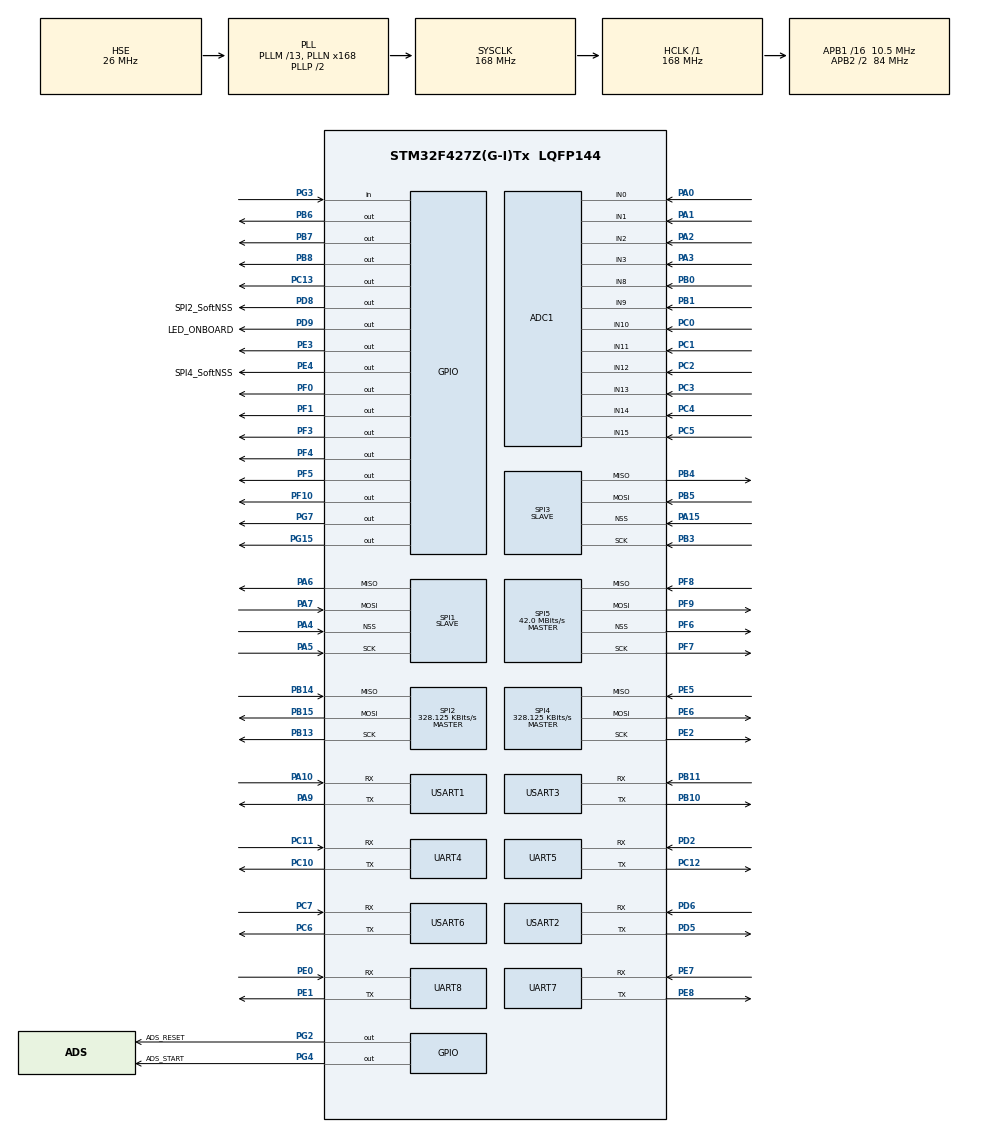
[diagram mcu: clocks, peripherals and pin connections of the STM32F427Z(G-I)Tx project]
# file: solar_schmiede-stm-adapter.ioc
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ADC1.Channel-1\#ChannelRegularConversion=ADC_CHANNEL_0
ADC1.Channel-10\#ChannelRegularConversion=ADC_CHANNEL_13
ADC1.Channel-11\#ChannelRegularConversion=ADC_CHANNEL_14
ADC1.Channel-12\#ChannelRegularConversion=ADC_CHANNEL_15
ADC1.Channel-2\#ChannelRegularConversion=ADC_CHANNEL_1
ADC1.Channel-3\#ChannelRegularConversion=ADC_CHANNEL_2
ADC1.Channel-4\#ChannelRegularConversion=ADC_CHANNEL_3
ADC1.Channel-5\#ChannelRegularConversion=ADC_CHANNEL_8
ADC1.Channel-6\#ChannelRegularConversion=ADC_CHANNEL_9
ADC1.Channel-7\#ChannelRegularConversion=ADC_CHANNEL_10
ADC1.Channel-8\#ChannelRegularConversion=ADC_CHANNEL_11
ADC1.Channel-9\#ChannelRegularConversion=ADC_CHANNEL_12
ADC1.DiscontinuousConvMode=DISABLE
ADC1.EOCSelection=ADC_EOC_SEQ_CONV
ADC1.NbrOfConversion=12
ADC1.NbrOfConversionFlag=1
ADC1.Rank-1\#ChannelRegularConversion=1
ADC1.Rank-10\#ChannelRegularConversion=10
ADC1.Rank-11\#ChannelRegularConversion=11
ADC1.Rank-12\#ChannelRegularConversion=12
ADC1.Rank-2\#ChannelRegularConversion=2
ADC1.Rank-3\#ChannelRegularConversion=3
ADC1.Rank-4\#ChannelRegularConversion=4
ADC1.Rank-5\#ChannelRegularConversion=5
ADC1.Rank-6\#ChannelRegularConversion=6
ADC1.Rank-7\#ChannelRegularConversion=7
ADC1.Rank-8\#ChannelRegularConversion=8
ADC1.Rank-9\#ChannelRegularConversion=9
ADC1.SamplingTime-1\#ChannelRegularConversion=ADC_SAMPLETIME_3CYCLES
ADC1.SamplingTime-10\#ChannelRegularConversion=ADC_SAMPLETIME_3CYCLES
ADC1.SamplingTime-11\#ChannelRegularConversion=ADC_SAMPLETIME_3CYCLES
ADC1.SamplingTime-12\#ChannelRegularConversion=ADC_SAMPLETIME_3CYCLES
ADC1.SamplingTime-2\#ChannelRegularConversion=ADC_SAMPLETIME_3CYCLES
ADC1.SamplingTime-3\#ChannelRegularConversion=ADC_SAMPLETIME_3CYCLES
ADC1.SamplingTime-4\#ChannelRegularConversion=ADC_SAMPLETIME_3CYCLES
ADC1.SamplingTime-5\#ChannelRegularConversion=ADC_SAMPLETIME_3CYCLES
ADC1.SamplingTime-6\#ChannelRegularConversion=ADC_SAMPLETIME_3CYCLES
ADC1.SamplingTime-7\#ChannelRegularConversion=ADC_SAMPLETIME_3CYCLES
ADC1.SamplingTime-8\#ChannelRegularConversion=ADC_SAMPLETIME_3CYCLES
ADC1.SamplingTime-9\#ChannelRegularConversion=ADC_SAMPLETIME_3CYCLES
ADC1.ScanConvMode=ENABLE
ADC1.master=1
Dma.ADC1.0.Direction=DMA_PERIPH_TO_MEMORY
Dma.ADC1.0.FIFOMode=DMA_FIFOMODE_DISABLE
Dma.ADC1.0.Instance=DMA2_Stream0
Dma.ADC1.0.MemDataAlignment=DMA_MDATAALIGN_HALFWORD
Dma.ADC1.0.MemInc=DMA_MINC_ENABLE
Dma.ADC1.0.Mode=DMA_NORMAL
Dma.ADC1.0.PeriphDataAlignment=DMA_PDATAALIGN_HALFWORD
Dma.ADC1.0.PeriphInc=DMA_PINC_DISABLE
Dma.ADC1.0.Priority=DMA_PRIORITY_LOW
Dma.Request0=ADC1
Dma.Request1=USART6_RX
Dma.Request2=USART3_RX
Dma.Request3=USART2_RX
Dma.Request4=USART1_RX
Dma.Request5=UART8_RX
Dma.Request6=UART7_RX
Dma.Request7=UART5_RX
Dma.Request8=UART4_RX
Dma.UART4_RX.8.Direction=DMA_PERIPH_TO_MEMORY
Dma.UART4_RX.8.FIFOMode=DMA_FIFOMODE_DISABLE
Dma.UART4_RX.8.Instance=DMA1_Stream2
Dma.UART4_RX.8.MemDataAlignment=DMA_MDATAALIGN_BYTE
Dma.UART4_RX.8.MemInc=DMA_MINC_ENABLE
Dma.UART4_RX.8.Mode=DMA_NORMAL
Dma.UART4_RX.8.PeriphDataAlignment=DMA_PDATAALIGN_BYTE
Dma.UART4_RX.8.PeriphInc=DMA_PINC_DISABLE
Dma.UART4_RX.8.Priority=DMA_PRIORITY_LOW
Dma.UART5_RX.7.Direction=DMA_PERIPH_TO_MEMORY
Dma.UART5_RX.7.FIFOMode=DMA_FIFOMODE_DISABLE
Dma.UART5_RX.7.Instance=DMA1_Stream0
Dma.UART5_RX.7.MemDataAlignment=DMA_MDATAALIGN_BYTE
Dma.UART5_RX.7.MemInc=DMA_MINC_ENABLE
Dma.UART5_RX.7.Mode=DMA_NORMAL
Dma.UART5_RX.7.PeriphDataAlignment=DMA_PDATAALIGN_BYTE
Dma.UART5_RX.7.PeriphInc=DMA_PINC_DISABLE
Dma.UART5_RX.7.Priority=DMA_PRIORITY_LOW
Dma.UART7_RX.6.Direction=DMA_PERIPH_TO_MEMORY
Dma.UART7_RX.6.FIFOMode=DMA_FIFOMODE_DISABLE
Dma.UART7_RX.6.Instance=DMA1_Stream3
Dma.UART7_RX.6.MemDataAlignment=DMA_MDATAALIGN_BYTE
Dma.UART7_RX.6.MemInc=DMA_MINC_ENABLE
Dma.UART7_RX.6.Mode=DMA_NORMAL
Dma.UART7_RX.6.PeriphDataAlignment=DMA_PDATAALIGN_BYTE
Dma.UART7_RX.6.PeriphInc=DMA_PINC_DISABLE
Dma.UART7_RX.6.Priority=DMA_PRIORITY_LOW
Dma.UART8_RX.5.Direction=DMA_PERIPH_TO_MEMORY
Dma.UART8_RX.5.FIFOMode=DMA_FIFOMODE_DISABLE
Dma.UART8_RX.5.Instance=DMA1_Stream6
Dma.UART8_RX.5.MemDataAlignment=DMA_MDATAALIGN_BYTE
Dma.UART8_RX.5.MemInc=DMA_MINC_ENABLE
Dma.UART8_RX.5.Mode=DMA_NORMAL
Dma.UART8_RX.5.PeriphDataAlignment=DMA_PDATAALIGN_BYTE
Dma.UART8_RX.5.PeriphInc=DMA_PINC_DISABLE
Dma.UART8_RX.5.Priority=DMA_PRIORITY_LOW
Dma.USART1_RX.4.Direction=DMA_PERIPH_TO_MEMORY
Dma.USART1_RX.4.FIFOMode=DMA_FIFOMODE_DISABLE
Dma.USART1_RX.4.Instance=DMA2_Stream2
Dma.USART1_RX.4.MemDataAlignment=DMA_MDATAALIGN_BYTE
Dma.USART1_RX.4.MemInc=DMA_MINC_ENABLE
Dma.USART1_RX.4.Mode=DMA_NORMAL
Dma.USART1_RX.4.PeriphDataAlignment=DMA_PDATAALIGN_BYTE
Dma.USART1_RX.4.PeriphInc=DMA_PINC_DISABLE
Dma.USART1_RX.4.Priority=DMA_PRIORITY_LOW
Dma.USART2_RX.3.Direction=DMA_PERIPH_TO_MEMORY
Dma.USART2_RX.3.FIFOMode=DMA_FIFOMODE_DISABLE
Dma.USART2_RX.3.Instance=DMA1_Stream5
Dma.USART2_RX.3.MemDataAlignment=DMA_MDATAALIGN_BYTE
Dma.USART2_RX.3.MemInc=DMA_MINC_ENABLE
Dma.USART2_RX.3.Mode=DMA_NORMAL
Dma.USART2_RX.3.PeriphDataAlignment=DMA_PDATAALIGN_BYTE
Dma.USART2_RX.3.PeriphInc=DMA_PINC_DISABLE
Dma.USART2_RX.3.Priority=DMA_PRIORITY_LOW
Dma.USART3_RX.2.Direction=DMA_PERIPH_TO_MEMORY
Dma.USART3_RX.2.FIFOMode=DMA_FIFOMODE_DISABLE
Dma.USART3_RX.2.Instance=DMA1_Stream1
Dma.USART3_RX.2.MemDataAlignment=DMA_MDATAALIGN_BYTE
Dma.USART3_RX.2.MemInc=DMA_MINC_ENABLE
Dma.USART3_RX.2.Mode=DMA_NORMAL
Dma.USART3_RX.2.PeriphDataAlignment=DMA_PDATAALIGN_BYTE
Dma.USART3_RX.2.PeriphInc=DMA_PINC_DISABLE
Dma.USART3_RX.2.Priority=DMA_PRIORITY_LOW
Dma.USART6_RX.1.Direction=DMA_PERIPH_TO_MEMORY
Dma.USART6_RX.1.FIFOMode=DMA_FIFOMODE_DISABLE
Dma.USART6_RX.1.Instance=DMA2_Stream1
Dma.USART6_RX.1.MemDataAlignment=DMA_MDATAALIGN_BYTE
Dma.USART6_RX.1.MemInc=DMA_MINC_ENABLE
Dma.USART6_RX.1.Mode=DMA_NORMAL
Dma.USART6_RX.1.PeriphDataAlignment=DMA_PDATAALIGN_BYTE
Dma.USART6_RX.1.PeriphInc=DMA_PINC_DISABLE
Dma.USART6_RX.1.Priority=DMA_PRIORITY_LOW
FREERTOS.BinarySemaphores01=spi_rx,Dynamic,NULL,Depleted
FREERTOS.Mutexes01=adcBufReadMutex,Dynamic,NULL,Available
FREERTOS.Queues01=uartQueue,20,17,1,Dynamic,NULL,NULL
FREERTOS.Tasks01=defaultTask,24,128,StartDefaultTask,Default,NULL,Dynamic,NULL,NULL;logTask,41,128,logTaskEntry,Default,NULL,Dynamic,NULL,NULL;adcReadTask,24,128,adcReadTaskEntry,Default,NULL,Dynamic,NULL,NULL;huartTask,26,256,huartTaskEntry,As external,NULL,Dynamic,NULL,NULL;adsReadTask,24,128,adsTaskEntry,Default,NULL,Dynamic,NULL,NULL
FREERTOS.configUSE_NEWLIB_REENTRANT=1
FREERTOS.configUSE_PREEMPTION=1
Mcu.Family=STM32F4
Mcu.Name=STM32F427Z(G-I)Tx
Mcu.Package=LQFP144
Mcu.UserConstants=mbus_uart_baud,2400
NVIC.DMA1_Stream0_IRQn=true\:5\:0\:false\:false\:true\:true\:false\:true\:true
NVIC.DMA1_Stream1_IRQn=true\:5\:0\:false\:false\:true\:true\:false\:true\:true
NVIC.DMA1_Stream2_IRQn=true\:5\:0\:false\:false\:true\:true\:false\:true\:true
NVIC.DMA1_Stream3_IRQn=true\:5\:0\:false\:false\:true\:true\:false\:true\:true
NVIC.DMA1_Stream5_IRQn=true\:5\:0\:false\:false\:true\:true\:false\:true\:true
NVIC.DMA1_Stream6_IRQn=true\:5\:0\:false\:false\:true\:true\:false\:true\:true
NVIC.DMA2_Stream0_IRQn=true\:5\:0\:false\:false\:true\:true\:false\:true\:true
NVIC.DMA2_Stream1_IRQn=true\:5\:0\:false\:false\:true\:true\:false\:true\:true
NVIC.DMA2_Stream2_IRQn=true\:5\:0\:false\:false\:true\:true\:false\:true\:true
NVIC.PriorityGroup=NVIC_PRIORITYGROUP_4
NVIC.TIM6_DAC_IRQn=true\:15\:0\:false\:false\:true\:false\:false\:true\:true
NVIC.TimeBase=TIM6_DAC_IRQn
NVIC.TimeBaseIP=TIM6
PA0/WKUP.Signal=ADCx_IN0
PA1.Signal=ADCx_IN1
PA10.Mode=Asynchronous
PA10.Signal=USART1_RX
PA13.Mode=Serial_Wire
PA13.Signal=SYS_JTMS-SWDIO
PA14.Mode=Serial_Wire
PA14.Signal=SYS_JTCK-SWCLK
PA15.GPIO_Speed=GPIO_SPEED_FREQ_VERY_HIGH
PA15.Mode=NSS_Signal_Hard_Input
PA15.Signal=SPI3_NSS
PA2.Signal=ADCx_IN2
PA3.Signal=ADCx_IN3
PA4.Mode=NSS_Signal_Hard_Input
PA4.Signal=SPI1_NSS
PA5.GPIO_Speed=GPIO_SPEED_FREQ_VERY_HIGH
PA5.Mode=Full_Duplex_Slave
PA5.Signal=SPI1_SCK
PA6.GPIO_Mode=GPIO_MODE_AF_PP
PA6.GPIO_PuPd=GPIO_NOPULL
PA6.GPIO_Speed=GPIO_SPEED_FREQ_VERY_HIGH
PA6.Mode=Full_Duplex_Slave
PA6.Signal=SPI1_MISO
PA7.GPIO_Speed=GPIO_SPEED_FREQ_VERY_HIGH
PA7.Mode=Full_Duplex_Slave
PA7.Signal=SPI1_MOSI
PA9.Mode=Asynchronous
PA9.Signal=USART1_TX
PB0.Signal=ADCx_IN8
PB1.Signal=ADCx_IN9
PB10.Mode=Asynchronous
PB10.Signal=USART3_TX
PB11.Mode=Asynchronous
PB11.Signal=USART3_RX
PB13.Mode=Full_Duplex_Master
PB13.Signal=SPI2_SCK
PB14.Mode=Full_Duplex_Master
PB14.Signal=SPI2_MISO
PB15.Mode=Full_Duplex_Master
PB15.Signal=SPI2_MOSI
PB3.GPIO_Speed=GPIO_SPEED_FREQ_VERY_HIGH
PB3.Mode=Full_Duplex_Slave
PB3.Signal=SPI3_SCK
PB4.GPIO_Speed=GPIO_SPEED_FREQ_VERY_HIGH
PB4.Mode=Full_Duplex_Slave
PB4.Signal=SPI3_MISO
PB5.GPIO_Speed=GPIO_SPEED_FREQ_VERY_HIGH
PB5.Mode=Full_Duplex_Slave
PB5.Signal=SPI3_MOSI
PB6.Signal=GPIO_Output
PB7.Signal=GPIO_Output
PB8.Signal=GPIO_Output
PC0.Signal=ADCx_IN10
PC1.Signal=ADCx_IN11
PC10.Mode=Asynchronous
PC10.Signal=UART4_TX
PC11.Mode=Asynchronous
PC11.Signal=UART4_RX
PC12.Mode=Asynchronous
PC12.Signal=UART5_TX
PC13.Signal=GPIO_Output
PC2.Signal=ADCx_IN12
PC3.Signal=ADCx_IN13
PC4.Signal=ADCx_IN14
PC5.Signal=ADCx_IN15
PC6.Mode=Asynchronous
PC6.Signal=USART6_TX
PC7.Mode=Asynchronous
PC7.Signal=USART6_RX
PD2.Mode=Asynchronous
PD2.Signal=UART5_RX
PD5.Mode=Asynchronous
PD5.Signal=USART2_TX
PD6.Mode=Asynchronous
PD6.Signal=USART2_RX
PD8.GPIO_Label=SPI2_SoftNSS
PD8.Signal=GPIO_Output
PD9.GPIO_Label=LED_ONBOARD
PD9.Signal=GPIO_Output
PE0.Mode=Asynchronous
PE0.Signal=UART8_RX
PE1.Mode=Asynchronous
PE1.Signal=UART8_TX
PE2.Mode=Full_Duplex_Master
PE2.Signal=SPI4_SCK
PE3.Signal=GPIO_Output
PE4.GPIO_Label=SPI4_SoftNSS
PE4.Signal=GPIO_Output
PE5.Mode=Full_Duplex_Master
PE5.Signal=SPI4_MISO
PE6.Mode=Full_Duplex_Master
PE6.Signal=SPI4_MOSI
PE7.Mode=Asynchronous
PE7.Signal=UART7_RX
PE8.Mode=Asynchronous
PE8.Signal=UART7_TX
PF0.Signal=GPIO_Output
PF1.Signal=GPIO_Output
PF10.Signal=GPIO_Output
PF3.Signal=GPIO_Output
PF4.Signal=GPIO_Output
PF5.Signal=GPIO_Output
PF6.Mode=NSS_Signal_Hard_Output
PF6.Signal=SPI5_NSS
PF7.Mode=Full_Duplex_Master
PF7.Signal=SPI5_SCK
PF8.Mode=Full_Duplex_Master
PF8.Signal=SPI5_MISO
PF9.Mode=Full_Duplex_Master
PF9.Signal=SPI5_MOSI
PG15.Signal=GPIO_Output
PG2.GPIO_Label=ADS_RESET
PG2.PinState=GPIO_PIN_SET
PG2.Signal=GPIO_Output
PG3.Signal=GPIO_Input
PG4.GPIO_Label=ADS_START
PG4.PinState=GPIO_PIN_SET
PG4.Signal=GPIO_Output
PG7.Signal=GPIO_Output
PH0/OSC_IN.Mode=HSE-External-Oscillator
PH0/OSC_IN.Signal=RCC_OSC_IN
PH1/OSC_OUT.Mode=HSE-External-Oscillator
PH1/OSC_OUT.Signal=RCC_OSC_OUT
ProjectManager.HeapSize=0x200
ProjectManager.StackSize=0x400
ProjectManager.TargetToolchain=STM32CubeIDE
RCC.48MHZClocksFreq_Value=48000000
RCC.AHBFreq_Value=168000000
RCC.APB1CLKDivider=RCC_HCLK_DIV16
RCC.APB1Freq_Value=10500000
RCC.APB1TimFreq_Value=21000000
RCC.APB2CLKDivider=RCC_HCLK_DIV2
RCC.APB2Freq_Value=84000000
RCC.APB2TimFreq_Value=168000000
RCC.CortexFreq_Value=168000000
RCC.EnbaleCSS=true
RCC.HCLKFreq_Value=168000000
RCC.HSE_VALUE=26000000
RCC.HSI_VALUE=16000000
RCC.LSE_VALUE=32768
RCC.PLLM=13
RCC.PLLN=168
RCC.PLLQ=7
RCC.PLLSourceVirtual=RCC_PLLSOURCE_HSE
RCC.SYSCLKFreq_VALUE=168000000
RCC.SYSCLKSource=RCC_SYSCLKSOURCE_PLLCLK
RCC.VCOOutputFreq_Value=336000000
SH.ADCx_IN0.0=ADC1_IN0,IN0
SH.ADCx_IN1.0=ADC1_IN1,IN1
SH.ADCx_IN10.0=ADC1_IN10,IN10
SH.ADCx_IN11.0=ADC1_IN11,IN11
SH.ADCx_IN12.0=ADC1_IN12,IN12
SH.ADCx_IN13.0=ADC1_IN13,IN13
SH.ADCx_IN14.0=ADC1_IN14,IN14
SH.ADCx_IN15.0=ADC1_IN15,IN15
SH.ADCx_IN2.0=ADC1_IN2,IN2
SH.ADCx_IN3.0=ADC1_IN3,IN3
SH.ADCx_IN8.0=ADC1_IN8,IN8
SH.ADCx_IN9.0=ADC1_IN9,IN9
SPI1.Direction=SPI_DIRECTION_2LINES
SPI1.Mode=SPI_MODE_SLAVE
SPI1.VirtualNSS=VM_NSSHARD
SPI1.VirtualType=VM_SLAVE
SPI2.BaudRatePrescaler=SPI_BAUDRATEPRESCALER_32
SPI2.CalculateBaudRate=328.125 KBits/s
SPI2.Direction=SPI_DIRECTION_2LINES
SPI2.Mode=SPI_MODE_MASTER
SPI2.VirtualType=VM_MASTER
SPI3.Direction=SPI_DIRECTION_2LINES
SPI3.Mode=SPI_MODE_SLAVE
SPI3.VirtualNSS=VM_NSSHARD
SPI3.VirtualType=VM_SLAVE
SPI4.BaudRatePrescaler=SPI_BAUDRATEPRESCALER_256
SPI4.CLKPhase=SPI_PHASE_2EDGE
SPI4.CalculateBaudRate=328.125 KBits/s
SPI4.Direction=SPI_DIRECTION_2LINES
SPI4.Mode=SPI_MODE_MASTER
SPI4.VirtualType=VM_MASTER
SPI5.BaudRatePrescaler=SPI_BAUDRATEPRESCALER_2
SPI5.CalculateBaudRate=42.0 MBits/s
SPI5.Direction=SPI_DIRECTION_2LINES
SPI5.Mode=SPI_MODE_MASTER
SPI5.VirtualNSS=VM_NSSHARD
SPI5.VirtualType=VM_MASTER
UART4.BaudRate=mbus_uart_baud
UART4.VirtualMode=Asynchronous
UART5.BaudRate=mbus_uart_baud
UART5.VirtualMode=Asynchronous
UART7.BaudRate=mbus_uart_baud
UART7.VirtualMode=Asynchronous
UART8.BaudRate=mbus_uart_baud
UART8.VirtualMode=Asynchronous
USART1.BaudRate=mbus_uart_baud
USART1.VirtualMode=VM_ASYNC
USART2.BaudRate=mbus_uart_baud
USART2.VirtualMode=VM_ASYNC
USART3.BaudRate=mbus_uart_baud
USART3.VirtualMode=VM_ASYNC
USART6.BaudRate=mbus_uart_baud
USART6.VirtualMode=VM_ASYNC
VP_FREERTOS_VS_CMSIS_V2.Mode=CMSIS_V2
VP_SYS_VS_tim6.Mode=TIM6
board=custom

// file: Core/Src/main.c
/* USER CODE BEGIN Header */
/**
 ******************************************************************************
 * @file           : main.c
 * @brief          : Main program body
 ******************************************************************************
 * @attention
 *
 * Copyright (c) 2025 STMicroelectronics.
 * All rights reserved.
 *
 * This software is licensed under terms that can be found in the LICENSE file
 * in the root directory of this software component.
 * If no LICENSE file comes with this software, it is provided AS-IS.
 *
 ******************************************************************************
 */
/* USER CODE END Header */
#include "main.h"
#include "cmsis_os.h"

/* USER CODE BEGIN Includes */

#include "string.h"
#include "bus_node.h"
#include "huart_task.h"
#include "ads124s08.h"

/* USER CODE END Includes */

ADC_HandleTypeDef hadc1;
DMA_HandleTypeDef hdma_adc1;

SPI_HandleTypeDef hspi1;
SPI_HandleTypeDef hspi2;
SPI_HandleTypeDef hspi3;
SPI_HandleTypeDef hspi4;
SPI_HandleTypeDef hspi5;

UART_HandleTypeDef huart4;
UART_HandleTypeDef huart5;
UART_HandleTypeDef huart7;
UART_HandleTypeDef huart8;
UART_HandleTypeDef huart1;
UART_HandleTypeDef huart2;
UART_HandleTypeDef huart3;
UART_HandleTypeDef huart6;
DMA_HandleTypeDef hdma_uart4_rx;
DMA_HandleTypeDef hdma_uart5_rx;
DMA_HandleTypeDef hdma_uart7_rx;
DMA_HandleTypeDef hdma_uart8_rx;
DMA_HandleTypeDef hdma_usart1_rx;
DMA_HandleTypeDef hdma_usart2_rx;
DMA_HandleTypeDef hdma_usart3_rx;
DMA_HandleTypeDef hdma_usart6_rx;

/* Definitions for defaultTask */
osThreadId_t defaultTaskHandle;
const osThreadAttr_t defaultTask_attributes = {
  .name = "defaultTask",
  .stack_size = 128 * 4,
  .priority = (osPriority_t) osPriorityNormal,
};
/* Definitions for logTask */
osThreadId_t logTaskHandle;
const osThreadAttr_t logTask_attributes = {
  .name = "logTask",
  .stack_size = 128 * 4,
  .priority = (osPriority_t) osPriorityHigh1,
};
/* Definitions for adcReadTask */
osThreadId_t adcReadTaskHandle;
const osThreadAttr_t adcReadTask_attributes = {
  .name = "adcReadTask",
  .stack_size = 128 * 4,
  .priority = (osPriority_t) osPriorityNormal,
};
/* Definitions for huartTask */
osThreadId_t huartTaskHandle;
const osThreadAttr_t huartTask_attributes = {
  .name = "huartTask",
  .stack_size = 256 * 4,
  .priority = (osPriority_t) osPriorityNormal2,
};
/* Definitions for adsReadTask */
osThreadId_t adsReadTaskHandle;
const osThreadAttr_t adsReadTask_attributes = {
  .name = "adsReadTask",
  .stack_size = 128 * 4,
  .priority = (osPriority_t) osPriorityNormal,
};
/* Definitions for uartQueue */
osMessageQueueId_t uartQueueHandle;
const osMessageQueueAttr_t uartQueue_attributes = {
  .name = "uartQueue"
};
/* Definitions for adcBufReadMutex */
osMutexId_t adcBufReadMutexHandle;
const osMutexAttr_t adcBufReadMutex_attributes = {
  .name = "adcBufReadMutex"
};
/* Definitions for spi_rx */
osSemaphoreId_t spi_rxHandle;
const osSemaphoreAttr_t spi_rx_attributes = {
  .name = "spi_rx"
};

void SystemClock_Config(void);
static void MX_GPIO_Init(void);
static void MX_DMA_Init(void);
static void MX_SPI1_Init(void);
static void MX_UART4_Init(void);
static void MX_UART5_Init(void);
static void MX_UART7_Init(void);
static void MX_UART8_Init(void);
static void MX_USART1_UART_Init(void);
static void MX_USART2_UART_Init(void);
static void MX_USART3_UART_Init(void);
static void MX_USART6_UART_Init(void);
static void MX_SPI3_Init(void);
static void MX_SPI4_Init(void);
static void MX_SPI5_Init(void);
static void MX_ADC1_Init(void);
static void MX_SPI2_Init(void);
void StartDefaultTask(void *argument);
void logTaskEntry(void *argument);
void adcReadTaskEntry(void *argument);
extern void huartTaskEntry(void *argument);
void adsTaskEntry(void *argument);

/* USER CODE BEGIN 0 */

uint16_t adcReadings[12] = { 0 };
uint16_t externalADCReadings[11] = { 0 };
volatile int isADCFinished = 0;

void HAL_ADC_ConvCpltCallback(ADC_HandleTypeDef *hadc) {
	isADCFinished = 1;
}

/* USER CODE END 0 */

int main(void)
{

  /* MCU Configuration--------------------------------------------------------*/

  /* Reset of all peripherals, Initializes the Flash interface and the Systick. */
  HAL_Init();

  /* Configure the system clock */
  SystemClock_Config();

  /* Initialize all configured peripherals */
  MX_GPIO_Init();
  MX_DMA_Init();
  MX_SPI1_Init();
  MX_UART4_Init();
  MX_UART5_Init();
  MX_UART7_Init();
  MX_UART8_Init();
  MX_USART1_UART_Init();
  MX_USART2_UART_Init();
  MX_USART3_UART_Init();
  MX_USART6_UART_Init();
  MX_SPI3_Init();
  MX_SPI4_Init();
  MX_SPI5_Init();
  MX_ADC1_Init();
  MX_SPI2_Init();

  /* Init scheduler */
  osKernelInitialize();
  /* Create the mutex(es) */
  /* creation of adcBufReadMutex */
  adcBufReadMutexHandle = osMutexNew(&adcBufReadMutex_attributes);

  /* Create the semaphores(s) */
  /* creation of spi_rx */
  spi_rxHandle = osSemaphoreNew(1, 0, &spi_rx_attributes);

  /* Create the queue(s) */
  /* creation of uartQueue */
  uartQueueHandle = osMessageQueueNew (20, 17, &uartQueue_attributes);

  /* Create the thread(s) */
  /* creation of defaultTask */
  defaultTaskHandle = osThreadNew(StartDefaultTask, NULL, &defaultTask_attributes);

  /* creation of logTask */
  logTaskHandle = osThreadNew(logTaskEntry, NULL, &logTask_attributes);

  /* creation of adcReadTask */
  adcReadTaskHandle = osThreadNew(adcReadTaskEntry, NULL, &adcReadTask_attributes);

  /* creation of huartTask */
  huartTaskHandle = osThreadNew(huartTaskEntry, NULL, &huartTask_attributes);

  /* creation of adsReadTask */
  adsReadTaskHandle = osThreadNew(adsTaskEntry, NULL, &adsReadTask_attributes);

  /* Start scheduler */
  osKernelStart();

  /* We should never get here as control is now taken by the scheduler */

  /* Infinite loop */
	while (1) {

	}
}

void SystemClock_Config(void)
{
  RCC_OscInitTypeDef RCC_OscInitStruct = {0};
  RCC_ClkInitTypeDef RCC_ClkInitStruct = {0};

  /** Configure the main internal regulator output voltage
  */
  __HAL_RCC_PWR_CLK_ENABLE();
  __HAL_PWR_VOLTAGESCALING_CONFIG(PWR_REGULATOR_VOLTAGE_SCALE1);

  /** Initializes the RCC Oscillators according to the specified parameters
  * in the RCC_OscInitTypeDef structure.
  */
  RCC_OscInitStruct.OscillatorType = RCC_OSCILLATORTYPE_HSE;
  RCC_OscInitStruct.HSEState = RCC_HSE_ON;
  RCC_OscInitStruct.PLL.PLLState = RCC_PLL_ON;
  RCC_OscInitStruct.PLL.PLLSource = RCC_PLLSOURCE_HSE;
  RCC_OscInitStruct.PLL.PLLM = 13;
  RCC_OscInitStruct.PLL.PLLN = 168;
  RCC_OscInitStruct.PLL.PLLP = RCC_PLLP_DIV2;
  RCC_OscInitStruct.PLL.PLLQ = 7;
  if (HAL_RCC_OscConfig(&RCC_OscInitStruct) != HAL_OK)
  {
    Error_Handler();
  }

  /** Initializes the CPU, AHB and APB buses clocks
  */
  RCC_ClkInitStruct.ClockType = RCC_CLOCKTYPE_HCLK|RCC_CLOCKTYPE_SYSCLK
                              |RCC_CLOCKTYPE_PCLK1|RCC_CLOCKTYPE_PCLK2;
  RCC_ClkInitStruct.SYSCLKSource = RCC_SYSCLKSOURCE_PLLCLK;
  RCC_ClkInitStruct.AHBCLKDivider = RCC_SYSCLK_DIV1;
  RCC_ClkInitStruct.APB1CLKDivider = RCC_HCLK_DIV16;
  RCC_ClkInitStruct.APB2CLKDivider = RCC_HCLK_DIV2;

  if (HAL_RCC_ClockConfig(&RCC_ClkInitStruct, FLASH_LATENCY_5) != HAL_OK)
  {
    Error_Handler();
  }

  /** Enables the Clock Security System
  */
  HAL_RCC_EnableCSS();
}

static void MX_ADC1_Init(void)
{

  ADC_ChannelConfTypeDef sConfig = {0};

  /** Configure the global features of the ADC (Clock, Resolution, Data Alignment and number of conversion)
  */
  hadc1.Instance = ADC1;
  hadc1.Init.ClockPrescaler = ADC_CLOCK_SYNC_PCLK_DIV4;
  hadc1.Init.Resolution = ADC_RESOLUTION_12B;
  hadc1.Init.ScanConvMode = ENABLE;
  hadc1.Init.ContinuousConvMode = DISABLE;
  hadc1.Init.DiscontinuousConvMode = DISABLE;
  hadc1.Init.ExternalTrigConvEdge = ADC_EXTERNALTRIGCONVEDGE_NONE;
  hadc1.Init.ExternalTrigConv = ADC_SOFTWARE_START;
  hadc1.Init.DataAlign = ADC_DATAALIGN_RIGHT;
  hadc1.Init.NbrOfConversion = 12;
  hadc1.Init.DMAContinuousRequests = DISABLE;
  hadc1.Init.EOCSelection = ADC_EOC_SEQ_CONV;
  if (HAL_ADC_Init(&hadc1) != HAL_OK)
  {
    Error_Handler();
  }

  /** Configure for the selected ADC regular channel its corresponding rank in the sequencer and its sample time.
  */
  sConfig.Channel = ADC_CHANNEL_0;
  sConfig.Rank = 1;
  sConfig.SamplingTime = ADC_SAMPLETIME_3CYCLES;
  if (HAL_ADC_ConfigChannel(&hadc1, &sConfig) != HAL_OK)
  {
    Error_Handler();
  }

  /** Configure for the selected ADC regular channel its corresponding rank in the sequencer and its sample time.
  */
  sConfig.Channel = ADC_CHANNEL_1;
  sConfig.Rank = 2;
  if (HAL_ADC_ConfigChannel(&hadc1, &sConfig) != HAL_OK)
  {
    Error_Handler();
  }

  /** Configure for the selected ADC regular channel its corresponding rank in the sequencer and its sample time.
  */
  sConfig.Channel = ADC_CHANNEL_2;
  sConfig.Rank = 3;
  if (HAL_ADC_ConfigChannel(&hadc1, &sConfig) != HAL_OK)
  {
    Error_Handler();
  }

  /** Configure for the selected ADC regular channel its corresponding rank in the sequencer and its sample time.
  */
  sConfig.Channel = ADC_CHANNEL_3;
  sConfig.Rank = 4;
  if (HAL_ADC_ConfigChannel(&hadc1, &sConfig) != HAL_OK)
  {
    Error_Handler();
  }

  /** Configure for the selected ADC regular channel its corresponding rank in the sequencer and its sample time.
  */
  sConfig.Channel = ADC_CHANNEL_8;
  sConfig.Rank = 5;
  if (HAL_ADC_ConfigChannel(&hadc1, &sConfig) != HAL_OK)
  {
    Error_Handler();
  }

  /** Configure for the selected ADC regular channel its corresponding rank in the sequencer and its sample time.
  */
  sConfig.Channel = ADC_CHANNEL_9;
  sConfig.Rank = 6;
  if (HAL_ADC_ConfigChannel(&hadc1, &sConfig) != HAL_OK)
  {
    Error_Handler();
  }

  /** Configure for the selected ADC regular channel its corresponding rank in the sequencer and its sample time.
  */
  sConfig.Channel = ADC_CHANNEL_10;
  sConfig.Rank = 7;
  if (HAL_ADC_ConfigChannel(&hadc1, &sConfig) != HAL_OK)
  {
    Error_Handler();
  }

  /** Configure for the selected ADC regular channel its corresponding rank in the sequencer and its sample time.
  */
  sConfig.Channel = ADC_CHANNEL_11;
  sConfig.Rank = 8;
  if (HAL_ADC_ConfigChannel(&hadc1, &sConfig) != HAL_OK)
  {
    Error_Handler();
  }

  /** Configure for the selected ADC regular channel its corresponding rank in the sequencer and its sample time.
  */
  sConfig.Channel = ADC_CHANNEL_12;
  sConfig.Rank = 9;
  if (HAL_ADC_ConfigChannel(&hadc1, &sConfig) != HAL_OK)
  {
    Error_Handler();
  }

  /** Configure for the selected ADC regular channel its corresponding rank in the sequencer and its sample time.
  */
  sConfig.Channel = ADC_CHANNEL_13;
  sConfig.Rank = 10;
  if (HAL_ADC_ConfigChannel(&hadc1, &sConfig) != HAL_OK)
  {
    Error_Handler();
  }

  /** Configure for the selected ADC regular channel its corresponding rank in the sequencer and its sample time.
  */
  sConfig.Channel = ADC_CHANNEL_14;
  sConfig.Rank = 11;
  if (HAL_ADC_ConfigChannel(&hadc1, &sConfig) != HAL_OK)
  {
    Error_Handler();
  }

  /** Configure for the selected ADC regular channel its corresponding rank in the sequencer and its sample time.
  */
  sConfig.Channel = ADC_CHANNEL_15;
  sConfig.Rank = 12;
  if (HAL_ADC_ConfigChannel(&hadc1, &sConfig) != HAL_OK)
  {
    Error_Handler();
  }

}

static void MX_SPI1_Init(void)
{

  /* SPI1 parameter configuration*/
  hspi1.Instance = SPI1;
  hspi1.Init.Mode = SPI_MODE_SLAVE;
  hspi1.Init.Direction = SPI_DIRECTION_2LINES;
  hspi1.Init.DataSize = SPI_DATASIZE_8BIT;
  hspi1.Init.CLKPolarity = SPI_POLARITY_LOW;
  hspi1.Init.CLKPhase = SPI_PHASE_1EDGE;
  hspi1.Init.NSS = SPI_NSS_HARD_INPUT;
  hspi1.Init.FirstBit = SPI_FIRSTBIT_MSB;
  hspi1.Init.TIMode = SPI_TIMODE_DISABLE;
  hspi1.Init.CRCCalculation = SPI_CRCCALCULATION_DISABLE;
  hspi1.Init.CRCPolynomial = 10;
  if (HAL_SPI_Init(&hspi1) != HAL_OK)
  {
    Error_Handler();
  }

}

static void MX_SPI2_Init(void)
{

  /* SPI2 parameter configuration*/
  hspi2.Instance = SPI2;
  hspi2.Init.Mode = SPI_MODE_MASTER;
  hspi2.Init.Direction = SPI_DIRECTION_2LINES;
  hspi2.Init.DataSize = SPI_DATASIZE_8BIT;
  hspi2.Init.CLKPolarity = SPI_POLARITY_LOW;
  hspi2.Init.CLKPhase = SPI_PHASE_1EDGE;
  hspi2.Init.NSS = SPI_NSS_SOFT;
  hspi2.Init.BaudRatePrescaler = SPI_BAUDRATEPRESCALER_32;
  hspi2.Init.FirstBit = SPI_FIRSTBIT_MSB;
  hspi2.Init.TIMode = SPI_TIMODE_DISABLE;
  hspi2.Init.CRCCalculation = SPI_CRCCALCULATION_DISABLE;
  hspi2.Init.CRCPolynomial = 10;
  if (HAL_SPI_Init(&hspi2) != HAL_OK)
  {
    Error_Handler();
  }

}

static void MX_SPI3_Init(void)
{

  /* SPI3 parameter configuration*/
  hspi3.Instance = SPI3;
  hspi3.Init.Mode = SPI_MODE_SLAVE;
  hspi3.Init.Direction = SPI_DIRECTION_2LINES;
  hspi3.Init.DataSize = SPI_DATASIZE_8BIT;
  hspi3.Init.CLKPolarity = SPI_POLARITY_LOW;
  hspi3.Init.CLKPhase = SPI_PHASE_1EDGE;
  hspi3.Init.NSS = SPI_NSS_HARD_INPUT;
  hspi3.Init.FirstBit = SPI_FIRSTBIT_MSB;
  hspi3.Init.TIMode = SPI_TIMODE_DISABLE;
  hspi3.Init.CRCCalculation = SPI_CRCCALCULATION_DISABLE;
  hspi3.Init.CRCPolynomial = 10;
  if (HAL_SPI_Init(&hspi3) != HAL_OK)
  {
    Error_Handler();
  }

}

static void MX_SPI4_Init(void)
{

  /* SPI4 parameter configuration*/
  hspi4.Instance = SPI4;
  hspi4.Init.Mode = SPI_MODE_MASTER;
  hspi4.Init.Direction = SPI_DIRECTION_2LINES;
  hspi4.Init.DataSize = SPI_DATASIZE_8BIT;
  hspi4.Init.CLKPolarity = SPI_POLARITY_LOW;
  hspi4.Init.CLKPhase = SPI_PHASE_2EDGE;
  hspi4.Init.NSS = SPI_NSS_SOFT;
  hspi4.Init.BaudRatePrescaler = SPI_BAUDRATEPRESCALER_256;
  hspi4.Init.FirstBit = SPI_FIRSTBIT_MSB;
  hspi4.Init.TIMode = SPI_TIMODE_DISABLE;
  hspi4.Init.CRCCalculation = SPI_CRCCALCULATION_DISABLE;
  hspi4.Init.CRCPolynomial = 10;
  if (HAL_SPI_Init(&hspi4) != HAL_OK)
  {
    Error_Handler();
  }

}

static void MX_SPI5_Init(void)
{

  /* SPI5 parameter configuration*/
  hspi5.Instance = SPI5;
  hspi5.Init.Mode = SPI_MODE_MASTER;
  hspi5.Init.Direction = SPI_DIRECTION_2LINES;
  hspi5.Init.DataSize = SPI_DATASIZE_8BIT;
  hspi5.Init.CLKPolarity = SPI_POLARITY_LOW;
  hspi5.Init.CLKPhase = SPI_PHASE_1EDGE;
  hspi5.Init.NSS = SPI_NSS_HARD_OUTPUT;
  hspi5.Init.BaudRatePrescaler = SPI_BAUDRATEPRESCALER_2;
  hspi5.Init.FirstBit = SPI_FIRSTBIT_MSB;
  hspi5.Init.TIMode = SPI_TIMODE_DISABLE;
  hspi5.Init.CRCCalculation = SPI_CRCCALCULATION_DISABLE;
  hspi5.Init.CRCPolynomial = 10;
  if (HAL_SPI_Init(&hspi5) != HAL_OK)
  {
    Error_Handler();
  }

}

static void MX_UART4_Init(void)
{

  huart4.Instance = UART4;
  huart4.Init.BaudRate = mbus_uart_baud;
  huart4.Init.WordLength = UART_WORDLENGTH_8B;
  huart4.Init.StopBits = UART_STOPBITS_1;
  huart4.Init.Parity = UART_PARITY_NONE;
  huart4.Init.Mode = UART_MODE_TX_RX;
  huart4.Init.HwFlowCtl = UART_HWCONTROL_NONE;
  huart4.Init.OverSampling = UART_OVERSAMPLING_16;
  if (HAL_UART_Init(&huart4) != HAL_OK)
  {
    Error_Handler();
  }

}

static void MX_UART5_Init(void)
{

  huart5.Instance = UART5;
  huart5.Init.BaudRate = mbus_uart_baud;
  huart5.Init.WordLength = UART_WORDLENGTH_8B;
  huart5.Init.StopBits = UART_STOPBITS_1;
  huart5.Init.Parity = UART_PARITY_NONE;
  huart5.Init.Mode = UART_MODE_TX_RX;
  huart5.Init.HwFlowCtl = UART_HWCONTROL_NONE;
  huart5.Init.OverSampling = UART_OVERSAMPLING_16;
  if (HAL_UART_Init(&huart5) != HAL_OK)
  {
    Error_Handler();
  }

}

static void MX_UART7_Init(void)
{

  huart7.Instance = UART7;
  huart7.Init.BaudRate = mbus_uart_baud;
  huart7.Init.WordLength = UART_WORDLENGTH_8B;
  huart7.Init.StopBits = UART_STOPBITS_1;
  huart7.Init.Parity = UART_PARITY_NONE;
  huart7.Init.Mode = UART_MODE_TX_RX;
  huart7.Init.HwFlowCtl = UART_HWCONTROL_NONE;
  huart7.Init.OverSampling = UART_OVERSAMPLING_16;
  if (HAL_UART_Init(&huart7) != HAL_OK)
  {
    Error_Handler();
  }

}

static void MX_UART8_Init(void)
{

  huart8.Instance = UART8;
  huart8.Init.BaudRate = mbus_uart_baud;
  huart8.Init.WordLength = UART_WORDLENGTH_8B;
  huart8.Init.StopBits = UART_STOPBITS_1;
  huart8.Init.Parity = UART_PARITY_NONE;
  huart8.Init.Mode = UART_MODE_TX_RX;
  huart8.Init.HwFlowCtl = UART_HWCONTROL_NONE;
  huart8.Init.OverSampling = UART_OVERSAMPLING_16;
  if (HAL_UART_Init(&huart8) != HAL_OK)
  {
    Error_Handler();
  }

}

static void MX_USART1_UART_Init(void)
{

  huart1.Instance = USART1;
  huart1.Init.BaudRate = mbus_uart_baud;
  huart1.Init.WordLength = UART_WORDLENGTH_8B;
  huart1.Init.StopBits = UART_STOPBITS_1;
  huart1.Init.Parity = UART_PARITY_NONE;
  huart1.Init.Mode = UART_MODE_TX_RX;
  huart1.Init.HwFlowCtl = UART_HWCONTROL_NONE;
  huart1.Init.OverSampling = UART_OVERSAMPLING_16;
  if (HAL_UART_Init(&huart1) != HAL_OK)
  {
    Error_Handler();
  }

}

static void MX_USART2_UART_Init(void)
{

  huart2.Instance = USART2;
  huart2.Init.BaudRate = mbus_uart_baud;
  huart2.Init.WordLength = UART_WORDLENGTH_8B;
  huart2.Init.StopBits = UART_STOPBITS_1;
  huart2.Init.Parity = UART_PARITY_NONE;
  huart2.Init.Mode = UART_MODE_TX_RX;
  huart2.Init.HwFlowCtl = UART_HWCONTROL_NONE;
  huart2.Init.OverSampling = UART_OVERSAMPLING_16;
  if (HAL_UART_Init(&huart2) != HAL_OK)
  {
    Error_Handler();
  }

}

static void MX_USART3_UART_Init(void)
{

  huart3.Instance = USART3;
  huart3.Init.BaudRate = mbus_uart_baud;
  huart3.Init.WordLength = UART_WORDLENGTH_8B;
  huart3.Init.StopBits = UART_STOPBITS_1;
  huart3.Init.Parity = UART_PARITY_NONE;
  huart3.Init.Mode = UART_MODE_TX_RX;
  huart3.Init.HwFlowCtl = UART_HWCONTROL_NONE;
  huart3.Init.OverSampling = UART_OVERSAMPLING_16;
  if (HAL_UART_Init(&huart3) != HAL_OK)
  {
    Error_Handler();
  }

}

static void MX_USART6_UART_Init(void)
{

  huart6.Instance = USART6;
  huart6.Init.BaudRate = mbus_uart_baud;
  huart6.Init.WordLength = UART_WORDLENGTH_8B;
  huart6.Init.StopBits = UART_STOPBITS_1;
  huart6.Init.Parity = UART_PARITY_NONE;
  huart6.Init.Mode = UART_MODE_TX_RX;
  huart6.Init.HwFlowCtl = UART_HWCONTROL_NONE;
  huart6.Init.OverSampling = UART_OVERSAMPLING_16;
  if (HAL_UART_Init(&huart6) != HAL_OK)
  {
    Error_Handler();
  }

}

static void MX_DMA_Init(void)
{

  /* DMA controller clock enable */
  __HAL_RCC_DMA2_CLK_ENABLE();
  __HAL_RCC_DMA1_CLK_ENABLE();

  /* DMA interrupt init */
  /* DMA1_Stream0_IRQn interrupt configuration */
  HAL_NVIC_SetPriority(DMA1_Stream0_IRQn, 5, 0);
  HAL_NVIC_EnableIRQ(DMA1_Stream0_IRQn);
  /* DMA1_Stream1_IRQn interrupt configuration */
  HAL_NVIC_SetPriority(DMA1_Stream1_IRQn, 5, 0);
  HAL_NVIC_EnableIRQ(DMA1_Stream1_IRQn);
  /* DMA1_Stream2_IRQn interrupt configuration */
  HAL_NVIC_SetPriority(DMA1_Stream2_IRQn, 5, 0);
  HAL_NVIC_EnableIRQ(DMA1_Stream2_IRQn);
  /* DMA1_Stream3_IRQn interrupt configuration */
  HAL_NVIC_SetPriority(DMA1_Stream3_IRQn, 5, 0);
  HAL_NVIC_EnableIRQ(DMA1_Stream3_IRQn);
  /* DMA1_Stream5_IRQn interrupt configuration */
  HAL_NVIC_SetPriority(DMA1_Stream5_IRQn, 5, 0);
  HAL_NVIC_EnableIRQ(DMA1_Stream5_IRQn);
  /* DMA1_Stream6_IRQn interrupt configuration */
  HAL_NVIC_SetPriority(DMA1_Stream6_IRQn, 5, 0);
  HAL_NVIC_EnableIRQ(DMA1_Stream6_IRQn);
  /* DMA2_Stream0_IRQn interrupt configuration */
  HAL_NVIC_SetPriority(DMA2_Stream0_IRQn, 5, 0);
  HAL_NVIC_EnableIRQ(DMA2_Stream0_IRQn);
  /* DMA2_Stream1_IRQn interrupt configuration */
  HAL_NVIC_SetPriority(DMA2_Stream1_IRQn, 5, 0);
  HAL_NVIC_EnableIRQ(DMA2_Stream1_IRQn);
  /* DMA2_Stream2_IRQn interrupt configuration */
  HAL_NVIC_SetPriority(DMA2_Stream2_IRQn, 5, 0);
  HAL_NVIC_EnableIRQ(DMA2_Stream2_IRQn);

}

static void MX_GPIO_Init(void)
{
  GPIO_InitTypeDef GPIO_InitStruct = {0};

  /* GPIO Ports Clock Enable */
  __HAL_RCC_GPIOE_CLK_ENABLE();
  __HAL_RCC_GPIOC_CLK_ENABLE();
  __HAL_RCC_GPIOF_CLK_ENABLE();
  __HAL_RCC_GPIOH_CLK_ENABLE();
  __HAL_RCC_GPIOA_CLK_ENABLE();
  __HAL_RCC_GPIOB_CLK_ENABLE();
  __HAL_RCC_GPIOD_CLK_ENABLE();
  __HAL_RCC_GPIOG_CLK_ENABLE();

  /*Configure GPIO pin Output Level */
  HAL_GPIO_WritePin(GPIOE, GPIO_PIN_3|SPI4_SoftNSS_Pin, GPIO_PIN_RESET);

  /*Configure GPIO pin Output Level */
  HAL_GPIO_WritePin(GPIOC, GPIO_PIN_13, GPIO_PIN_RESET);

  /*Configure GPIO pin Output Level */
  HAL_GPIO_WritePin(GPIOF, GPIO_PIN_0|GPIO_PIN_1|GPIO_PIN_3|GPIO_PIN_4
                          |GPIO_PIN_5|GPIO_PIN_10, GPIO_PIN_RESET);

  /*Configure GPIO pin Output Level */
  HAL_GPIO_WritePin(GPIOD, SPI2_SoftNSS_Pin|LED_ONBOARD_Pin, GPIO_PIN_RESET);

  /*Configure GPIO pin Output Level */
  HAL_GPIO_WritePin(GPIOG, ADS_RESET_Pin|ADS_START_Pin, GPIO_PIN_SET);

  /*Configure GPIO pin Output Level */
  HAL_GPIO_WritePin(GPIOG, GPIO_PIN_7|GPIO_PIN_15, GPIO_PIN_RESET);

  /*Configure GPIO pin Output Level */
  HAL_GPIO_WritePin(GPIOB, GPIO_PIN_6|GPIO_PIN_7|GPIO_PIN_8, GPIO_PIN_RESET);

  /*Configure GPIO pins : PE3 SPI4_SoftNSS_Pin */
  GPIO_InitStruct.Pin = GPIO_PIN_3|SPI4_SoftNSS_Pin;
  GPIO_InitStruct.Mode = GPIO_MODE_OUTPUT_PP;
  GPIO_InitStruct.Pull = GPIO_NOPULL;
  GPIO_InitStruct.Speed = GPIO_SPEED_FREQ_LOW;
  HAL_GPIO_Init(GPIOE, &GPIO_InitStruct);

  /*Configure GPIO pin : PC13 */
  GPIO_InitStruct.Pin = GPIO_PIN_13;
  GPIO_InitStruct.Mode = GPIO_MODE_OUTPUT_PP;
  GPIO_InitStruct.Pull = GPIO_NOPULL;
  GPIO_InitStruct.Speed = GPIO_SPEED_FREQ_LOW;
  HAL_GPIO_Init(GPIOC, &GPIO_InitStruct);

  /*Configure GPIO pins : PF0 PF1 PF3 PF4
                           PF5 PF10 */
  GPIO_InitStruct.Pin = GPIO_PIN_0|GPIO_PIN_1|GPIO_PIN_3|GPIO_PIN_4
                          |GPIO_PIN_5|GPIO_PIN_10;
  GPIO_InitStruct.Mode = GPIO_MODE_OUTPUT_PP;
  GPIO_InitStruct.Pull = GPIO_NOPULL;
  GPIO_InitStruct.Speed = GPIO_SPEED_FREQ_LOW;
  HAL_GPIO_Init(GPIOF, &GPIO_InitStruct);

  /*Configure GPIO pins : SPI2_SoftNSS_Pin LED_ONBOARD_Pin */
  GPIO_InitStruct.Pin = SPI2_SoftNSS_Pin|LED_ONBOARD_Pin;
  GPIO_InitStruct.Mode = GPIO_MODE_OUTPUT_PP;
  GPIO_InitStruct.Pull = GPIO_NOPULL;
  GPIO_InitStruct.Speed = GPIO_SPEED_FREQ_LOW;
  HAL_GPIO_Init(GPIOD, &GPIO_InitStruct);

  /*Configure GPIO pins : ADS_RESET_Pin ADS_START_Pin PG7 PG15 */
  GPIO_InitStruct.Pin = ADS_RESET_Pin|ADS_START_Pin|GPIO_PIN_7|GPIO_PIN_15;
  GPIO_InitStruct.Mode = GPIO_MODE_OUTPUT_PP;
  GPIO_InitStruct.Pull = GPIO_NOPULL;
  GPIO_InitStruct.Speed = GPIO_SPEED_FREQ_LOW;
  HAL_GPIO_Init(GPIOG, &GPIO_InitStruct);

  /*Configure GPIO pin : PG3 */
  GPIO_InitStruct.Pin = GPIO_PIN_3;
  GPIO_InitStruct.Mode = GPIO_MODE_INPUT;
  GPIO_InitStruct.Pull = GPIO_NOPULL;
  HAL_GPIO_Init(GPIOG, &GPIO_InitStruct);

  /*Configure GPIO pins : PB6 PB7 PB8 */
  GPIO_InitStruct.Pin = GPIO_PIN_6|GPIO_PIN_7|GPIO_PIN_8;
  GPIO_InitStruct.Mode = GPIO_MODE_OUTPUT_PP;
  GPIO_InitStruct.Pull = GPIO_NOPULL;
  GPIO_InitStruct.Speed = GPIO_SPEED_FREQ_LOW;
  HAL_GPIO_Init(GPIOB, &GPIO_InitStruct);

}

void StartDefaultTask(void *argument)
{
  /* USER CODE BEGIN 5 */
	/* Infinite loop */
	for (;;) {
		osDelay(osWaitForever);
	}
  /* USER CODE END 5 */
}

void logTaskEntry(void *argument)
{
  /* USER CODE BEGIN logTaskEntry */

	BusNode_Init();

	HAL_GPIO_WritePin(SPI2_SoftNSS_GPIO_Port, SPI2_SoftNSS_Pin, GPIO_PIN_SET);
	/* Infinite loop */
	for (;;) {
		BusNode_RunLoop();
		osDelay(1);

	}
  /* USER CODE END logTaskEntry */
}

void adcReadTaskEntry(void *argument)
{
  /* USER CODE BEGIN adcReadTaskEntry */
	/* Infinite loop */

	// Initialize ADC readings array
	memset(adcReadings, 0, sizeof(adcReadings));

	// Use static buffer to avoid stack issues
	static uint16_t adcBuf[12] = { 0 };

	// Start ADC with DMA
	HAL_ADC_Start_DMA(&hadc1, (uint32_t*)adcBuf, 12);

	// Variables for timing
	uint32_t last_adc_update = 0;
	const uint32_t ADC_UPDATE_INTERVAL = 500; // 500ms interval for ADC updates

	for (;;) {
		uint32_t current_tick = osKernelGetTickCount();

		// Check if ADC conversion is complete
		if (isADCFinished == 1) {
			isADCFinished = 0;

			// Acquire mutex before updating shared data
			if (osMutexAcquire(adcBufReadMutexHandle, 100) == osOK) {
				// Copy ADC readings to shared buffer
				memcpy(adcReadings, adcBuf, sizeof(adcReadings));
				osMutexRelease(adcBufReadMutexHandle);

				// Update timestamp
				last_adc_update = current_tick;
			}

			// Restart ADC conversion
			HAL_ADC_Start_DMA(&hadc1, (uint32_t*)adcBuf, 12);
		}

		// If it's been too long since the last update, force a new conversion
		if (current_tick - last_adc_update > ADC_UPDATE_INTERVAL) {
			// Stop any ongoing conversion
			HAL_ADC_Stop_DMA(&hadc1);

			// Restart ADC conversion
			HAL_ADC_Start_DMA(&hadc1, (uint32_t*)adcBuf, 12);

			// Update timestamp to prevent multiple forced conversions
			last_adc_update = current_tick;
		}

		// Short delay to yield to other tasks
		osDelay(20);
	}
  /* USER CODE END adcReadTaskEntry */
}

/* USER CODE BEGIN Header_adsTaskEntry */
/**
 * @brief Function implementing the adsReadTask thread.
 * @param argument: Not used
 * @retval None
 */

long map(long x, long in_min, long in_max, long out_min, long out_max) {
  return (x - in_min) * (out_max - out_min) / (in_max - in_min) + out_min;
}
/* USER CODE END Header_adsTaskEntry */
void adsTaskEntry(void *argument)
{
  /* USER CODE BEGIN adsTaskEntry */
	/* Infinite loop */

	// Initialize the external ADC
	ADS124S08 adc = { .hspi = &hspi4, .nss_pin = SPI4_SoftNSS_Pin, .nss_port = GPIOE};
	ADS124S08_Init(&adc);

	// Set initial channel
	ADS124S08_SetInputChannel(&adc, 0, 13);

	// Start conversion
	ADS124S08_StartConversion(&adc);

	// Variables for timing
	uint32_t last_update = 0;
	const uint32_t UPDATE_INTERVAL = 500; // 500ms interval for updates

	for (;;) {
		uint32_t current_tick = osKernelGetTickCount();

		// Only update readings at the specified interval
		if (current_tick - last_update >= UPDATE_INTERVAL) {
			// Read all channels
			for (size_t i = 0; i < 11; i++) {
				// Set channel
				ADS124S08_SetInputChannel(&adc, i, 12);

				// Read data and shift right by 8 bits (to get 16-bit value)
				int32_t reading = ADS124S08_ReadData(&adc) >> 8;

				// Store reading
				externalADCReadings[i] = reading;

				// Small delay between channel readings to avoid SPI conflicts
				osDelay(5);
			}

			// Update timestamp
			last_update = current_tick;
		}

		// Yield to other tasks
		osDelay(20);
	}
  /* USER CODE END adsTaskEntry */
}

void HAL_TIM_PeriodElapsedCallback(TIM_HandleTypeDef *htim)
{
  if (htim->Instance == TIM6)
  {
    HAL_IncTick();
  }
}

void Error_Handler(void)
{
	__disable_irq();
	while (1) {
	}
}
